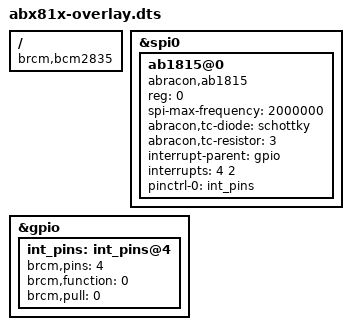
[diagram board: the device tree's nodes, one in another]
/dts-v1/;
/plugin/;

/ {
        compatible = "brcm,bcm2835";

        fragment@0 {
                target = <&spi0>;
                __overlay__ {
                        #address-cells = <1>;
			#size-cells = <0>;
                        status = "okay";

                        ab1815@0 {
                                compatible = "abracon,ab1815";
                                reg = <0>;
                                spi-max-frequency = <2000000>;
                                abracon,tc-diode = "schottky";
                                abracon,tc-resistor = <3>;

                                interrupt-parent = <&gpio>;
                                interrupts = <4 2>;
                                pinctrl-0 = <&int_pins>;
                                pinctrl-names = "default";

                                status = "okay";
                        };
                };
        };

        fragment@99 {
		target = <&gpio>;
		__overlay__ {
			int_pins: int_pins@4 {
                                brcm,pins = <4>;
                                brcm,function = <0>; /* in */
                                brcm,pull = <0>; /* none */
			};
		};
	};

};
